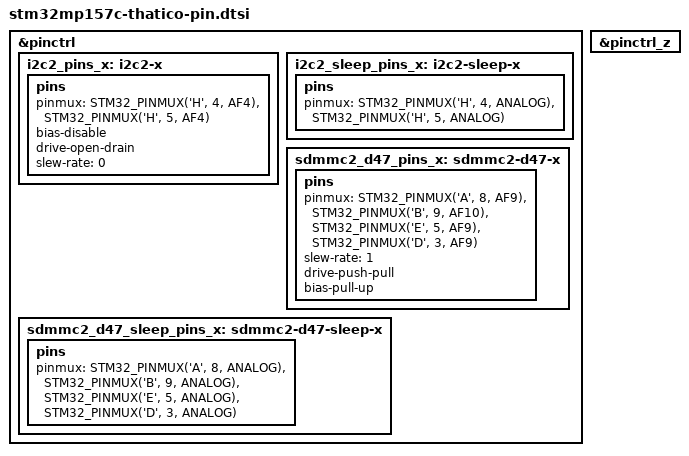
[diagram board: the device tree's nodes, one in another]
// SPDX-License-Identifier: (GPL-2.0+ OR BSD-3-Clause)
/*
 * Copyright (C) OneKiwi 2022 - All Rights Reserved
 * Author: Thanh Duong <thanh.duong.vs@gmail.com> for OneKiwi.
 */
#include <dt-bindings/pinctrl/stm32-pinfunc.h>

&pinctrl {
	i2c2_pins_x: i2c2-x {
		pins {
			pinmux = <STM32_PINMUX('H', 4, AF4)>, /* I2C2_SCL */
				 <STM32_PINMUX('H', 5, AF4)>; /* I2C2_SDA */
			bias-disable;
			drive-open-drain;
			slew-rate = <0>;
		};
	};

	i2c2_sleep_pins_x: i2c2-sleep-x {
		pins {
			pinmux = <STM32_PINMUX('H', 4, ANALOG)>, /* I2C2_SCL */
				 <STM32_PINMUX('H', 5, ANALOG)>; /* I2C2_SDA */
		};
	};
	
	sdmmc2_d47_pins_x: sdmmc2-d47-x {
		pins {
			pinmux = <STM32_PINMUX('A', 8, AF9)>, /* SDMMC2_D4 */
				 <STM32_PINMUX('B', 9, AF10)>, /* SDMMC2_D5 */
				 <STM32_PINMUX('E', 5, AF9)>, /* SDMMC2_D6 */
				 <STM32_PINMUX('D', 3, AF9)>; /* SDMMC2_D7 */
			slew-rate = <1>;
			drive-push-pull;
			bias-pull-up;
		};
	};

	sdmmc2_d47_sleep_pins_x: sdmmc2-d47-sleep-x {
		pins {
			pinmux = <STM32_PINMUX('A', 8, ANALOG)>, /* SDMMC2_D4 */
				 <STM32_PINMUX('B', 9, ANALOG)>, /* SDMMC2_D5 */
				 <STM32_PINMUX('E', 5, ANALOG)>, /* SDMMC2_D6 */
				 <STM32_PINMUX('D', 3, ANALOG)>; /* SDMMC2_D7 */
		};
	};
};
&pinctrl_z {
	
};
